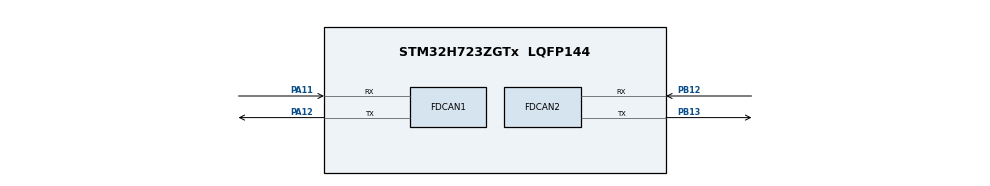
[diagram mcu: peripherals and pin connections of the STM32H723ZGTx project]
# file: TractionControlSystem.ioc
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CORTEX_M7.default_mode_Activation=1
FDCAN1.CalculateBaudRateNominal=2000000
FDCAN1.CalculateTimeBitNominal=500
FDCAN1.CalculateTimeQuantumNominal=166.66666666666666
FDCAN2.CalculateBaudRateNominal=2000000
FDCAN2.CalculateTimeBitNominal=500
FDCAN2.CalculateTimeQuantumNominal=166.66666666666666
Mcu.Family=STM32H7
Mcu.Name=STM32H723ZGTx
Mcu.Package=LQFP144
NVIC.PriorityGroup=NVIC_PRIORITYGROUP_4
PA11.Mode=FDCAN_Activate
PA11.Signal=FDCAN1_RX
PA12.Mode=FDCAN_Activate
PA12.Signal=FDCAN1_TX
PB12.Mode=FDCAN_Activate
PB12.Signal=FDCAN2_RX
PB13.Mode=FDCAN_Activate
PB13.Signal=FDCAN2_TX
ProjectManager.HeapSize=0x200
ProjectManager.StackSize=0x400
ProjectManager.TargetToolchain=STM32CubeIDE
RCC.ADCFreq_Value=129000000
RCC.APB1Freq_Value=96000000
RCC.APB2Freq_Value=96000000
RCC.APB3Freq_Value=96000000
RCC.APB4Freq_Value=96000000
RCC.CortexFreq_Value=192000000
RCC.D1PPRE=RCC_APB3_DIV2
RCC.D2PPRE1=RCC_APB1_DIV2
RCC.D2PPRE2=RCC_APB2_DIV2
RCC.D3PPRE=RCC_APB4_DIV2
RCC.DIVM1=4
RCC.DIVN1=12
RCC.DIVP1=1
RCC.HCLKFreq_Value=192000000
RCC.PLL2FRACN=0
RCC.PLL3FRACN=0
RCC.PLLFRACN=0
RCC.SYSCLKFreq_VALUE=192000000
RCC.SYSCLKSource=RCC_SYSCLKSOURCE_PLLCLK
RCC.USBFreq_Value=96000000
VP_MEMORYMAP_VS_MEMORYMAP.Mode=CurAppReg
board=custom

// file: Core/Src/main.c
/* USER CODE BEGIN Header */
/**
  ******************************************************************************
  * @file           : main.c
  * @brief          : Main program body
  ******************************************************************************
  * @attention
  *
  * Copyright (c) 2026 STMicroelectronics.
  * All rights reserved.
  *
  * This software is licensed under terms that can be found in the LICENSE file
  * in the root directory of this software component.
  * If no LICENSE file comes with this software, it is provided AS-IS.
  *
  ******************************************************************************
  */
/* USER CODE END Header */
#include "main.h"

/* USER CODE BEGIN Includes */

#include "tcs_app_main.h"  // Ana TCS fonksiyonları
#include "tcs_input_cond.h" // Veri besleme fonksiyonları

/* USER CODE END Includes */

FDCAN_HandleTypeDef hfdcan1;
FDCAN_HandleTypeDef hfdcan2;

void SystemClock_Config(void);
static void MPU_Config(void);
static void MX_GPIO_Init(void);
static void MX_FDCAN1_Init(void);
static void MX_FDCAN2_Init(void);

int main(void)
{

  /* MPU Configuration--------------------------------------------------------*/
  MPU_Config();

  /* MCU Configuration--------------------------------------------------------*/

  /* Reset of all peripherals, Initializes the Flash interface and the Systick. */
  HAL_Init();

  /* USER CODE BEGIN Init */
  TCS_Init();
  /* USER CODE END Init */

  /* Configure the system clock */
  SystemClock_Config();

  /* Initialize all configured peripherals */
  MX_GPIO_Init();
  MX_FDCAN1_Init();
  MX_FDCAN2_Init();

  /* Infinite loop */
  while (1)
  {

  }
}

void SystemClock_Config(void)
{
  RCC_OscInitTypeDef RCC_OscInitStruct = {0};
  RCC_ClkInitTypeDef RCC_ClkInitStruct = {0};

  /** Supply configuration update enable
  */
  HAL_PWREx_ConfigSupply(PWR_LDO_SUPPLY);

  /** Configure the main internal regulator output voltage
  */
  __HAL_PWR_VOLTAGESCALING_CONFIG(PWR_REGULATOR_VOLTAGE_SCALE1);

  while(!__HAL_PWR_GET_FLAG(PWR_FLAG_VOSRDY)) {}

  /** Initializes the RCC Oscillators according to the specified parameters
  * in the RCC_OscInitTypeDef structure.
  */
  RCC_OscInitStruct.OscillatorType = RCC_OSCILLATORTYPE_HSI;
  RCC_OscInitStruct.HSIState = RCC_HSI_DIV1;
  RCC_OscInitStruct.HSICalibrationValue = 64;
  RCC_OscInitStruct.PLL.PLLState = RCC_PLL_ON;
  RCC_OscInitStruct.PLL.PLLSource = RCC_PLLSOURCE_HSI;
  RCC_OscInitStruct.PLL.PLLM = 4;
  RCC_OscInitStruct.PLL.PLLN = 12;
  RCC_OscInitStruct.PLL.PLLP = 1;
  RCC_OscInitStruct.PLL.PLLQ = 2;
  RCC_OscInitStruct.PLL.PLLR = 2;
  RCC_OscInitStruct.PLL.PLLRGE = RCC_PLL1VCIRANGE_3;
  RCC_OscInitStruct.PLL.PLLVCOSEL = RCC_PLL1VCOWIDE;
  RCC_OscInitStruct.PLL.PLLFRACN = 0;
  if (HAL_RCC_OscConfig(&RCC_OscInitStruct) != HAL_OK)
  {
    Error_Handler();
  }

  /** Initializes the CPU, AHB and APB buses clocks
  */
  RCC_ClkInitStruct.ClockType = RCC_CLOCKTYPE_HCLK|RCC_CLOCKTYPE_SYSCLK
                              |RCC_CLOCKTYPE_PCLK1|RCC_CLOCKTYPE_PCLK2
                              |RCC_CLOCKTYPE_D3PCLK1|RCC_CLOCKTYPE_D1PCLK1;
  RCC_ClkInitStruct.SYSCLKSource = RCC_SYSCLKSOURCE_PLLCLK;
  RCC_ClkInitStruct.SYSCLKDivider = RCC_SYSCLK_DIV1;
  RCC_ClkInitStruct.AHBCLKDivider = RCC_HCLK_DIV1;
  RCC_ClkInitStruct.APB3CLKDivider = RCC_APB3_DIV2;
  RCC_ClkInitStruct.APB1CLKDivider = RCC_APB1_DIV2;
  RCC_ClkInitStruct.APB2CLKDivider = RCC_APB2_DIV2;
  RCC_ClkInitStruct.APB4CLKDivider = RCC_APB4_DIV2;

  if (HAL_RCC_ClockConfig(&RCC_ClkInitStruct, FLASH_LATENCY_2) != HAL_OK)
  {
    Error_Handler();
  }
}

static void MX_FDCAN1_Init(void)
{

  hfdcan1.Instance = FDCAN1;
  hfdcan1.Init.FrameFormat = FDCAN_FRAME_CLASSIC;
  hfdcan1.Init.Mode = FDCAN_MODE_NORMAL;
  hfdcan1.Init.AutoRetransmission = DISABLE;
  hfdcan1.Init.TransmitPause = DISABLE;
  hfdcan1.Init.ProtocolException = DISABLE;
  hfdcan1.Init.NominalPrescaler = 16;
  hfdcan1.Init.NominalSyncJumpWidth = 1;
  hfdcan1.Init.NominalTimeSeg1 = 1;
  hfdcan1.Init.NominalTimeSeg2 = 1;
  hfdcan1.Init.DataPrescaler = 1;
  hfdcan1.Init.DataSyncJumpWidth = 1;
  hfdcan1.Init.DataTimeSeg1 = 1;
  hfdcan1.Init.DataTimeSeg2 = 1;
  hfdcan1.Init.MessageRAMOffset = 0;
  hfdcan1.Init.StdFiltersNbr = 0;
  hfdcan1.Init.ExtFiltersNbr = 0;
  hfdcan1.Init.RxFifo0ElmtsNbr = 0;
  hfdcan1.Init.RxFifo0ElmtSize = FDCAN_DATA_BYTES_8;
  hfdcan1.Init.RxFifo1ElmtsNbr = 0;
  hfdcan1.Init.RxFifo1ElmtSize = FDCAN_DATA_BYTES_8;
  hfdcan1.Init.RxBuffersNbr = 0;
  hfdcan1.Init.RxBufferSize = FDCAN_DATA_BYTES_8;
  hfdcan1.Init.TxEventsNbr = 0;
  hfdcan1.Init.TxBuffersNbr = 0;
  hfdcan1.Init.TxFifoQueueElmtsNbr = 0;
  hfdcan1.Init.TxFifoQueueMode = FDCAN_TX_FIFO_OPERATION;
  hfdcan1.Init.TxElmtSize = FDCAN_DATA_BYTES_8;
  if (HAL_FDCAN_Init(&hfdcan1) != HAL_OK)
  {
    Error_Handler();
  }

}

static void MX_FDCAN2_Init(void)
{

  hfdcan2.Instance = FDCAN2;
  hfdcan2.Init.FrameFormat = FDCAN_FRAME_CLASSIC;
  hfdcan2.Init.Mode = FDCAN_MODE_NORMAL;
  hfdcan2.Init.AutoRetransmission = DISABLE;
  hfdcan2.Init.TransmitPause = DISABLE;
  hfdcan2.Init.ProtocolException = DISABLE;
  hfdcan2.Init.NominalPrescaler = 16;
  hfdcan2.Init.NominalSyncJumpWidth = 1;
  hfdcan2.Init.NominalTimeSeg1 = 1;
  hfdcan2.Init.NominalTimeSeg2 = 1;
  hfdcan2.Init.DataPrescaler = 1;
  hfdcan2.Init.DataSyncJumpWidth = 1;
  hfdcan2.Init.DataTimeSeg1 = 1;
  hfdcan2.Init.DataTimeSeg2 = 1;
  hfdcan2.Init.MessageRAMOffset = 0;
  hfdcan2.Init.StdFiltersNbr = 0;
  hfdcan2.Init.ExtFiltersNbr = 0;
  hfdcan2.Init.RxFifo0ElmtsNbr = 0;
  hfdcan2.Init.RxFifo0ElmtSize = FDCAN_DATA_BYTES_8;
  hfdcan2.Init.RxFifo1ElmtsNbr = 0;
  hfdcan2.Init.RxFifo1ElmtSize = FDCAN_DATA_BYTES_8;
  hfdcan2.Init.RxBuffersNbr = 0;
  hfdcan2.Init.RxBufferSize = FDCAN_DATA_BYTES_8;
  hfdcan2.Init.TxEventsNbr = 0;
  hfdcan2.Init.TxBuffersNbr = 0;
  hfdcan2.Init.TxFifoQueueElmtsNbr = 0;
  hfdcan2.Init.TxFifoQueueMode = FDCAN_TX_FIFO_OPERATION;
  hfdcan2.Init.TxElmtSize = FDCAN_DATA_BYTES_8;
  if (HAL_FDCAN_Init(&hfdcan2) != HAL_OK)
  {
    Error_Handler();
  }

}

static void MX_GPIO_Init(void)
{

  /* GPIO Ports Clock Enable */
  __HAL_RCC_GPIOB_CLK_ENABLE();
  __HAL_RCC_GPIOA_CLK_ENABLE();

}

 /* MPU Configuration */

void MPU_Config(void)
{
  MPU_Region_InitTypeDef MPU_InitStruct = {0};

  /* Disables the MPU */
  HAL_MPU_Disable();

  /** Initializes and configures the Region and the memory to be protected
  */
  MPU_InitStruct.Enable = MPU_REGION_ENABLE;
  MPU_InitStruct.Number = MPU_REGION_NUMBER0;
  MPU_InitStruct.BaseAddress = 0x0;
  MPU_InitStruct.Size = MPU_REGION_SIZE_4GB;
  MPU_InitStruct.SubRegionDisable = 0x87;
  MPU_InitStruct.TypeExtField = MPU_TEX_LEVEL0;
  MPU_InitStruct.AccessPermission = MPU_REGION_NO_ACCESS;
  MPU_InitStruct.DisableExec = MPU_INSTRUCTION_ACCESS_DISABLE;
  MPU_InitStruct.IsShareable = MPU_ACCESS_SHAREABLE;
  MPU_InitStruct.IsCacheable = MPU_ACCESS_NOT_CACHEABLE;
  MPU_InitStruct.IsBufferable = MPU_ACCESS_NOT_BUFFERABLE;

  HAL_MPU_ConfigRegion(&MPU_InitStruct);
  /* Enables the MPU */
  HAL_MPU_Enable(MPU_PRIVILEGED_DEFAULT);

}

void Error_Handler(void)
{
  __disable_irq();
  while (1)
  {
  }
}
